# PM_WDT register map
File version: 1
BCM2711 power-management watchdog
Registers are read-write, no defined reset value unless marked. A register's access mark holds for its fields unless they carry their own. Offsets are from the block's base; lines under a group give offsets from that group; [hi:lo] are bit positions; {n}, {i} and the like mark numbered series; 'fields as' and 'values as' point back to an identical list; <NAME> marks a mode.

## Memory map
0x00000000 PM_WDT size 0x28

## PM_WDT
Base 0x00000000
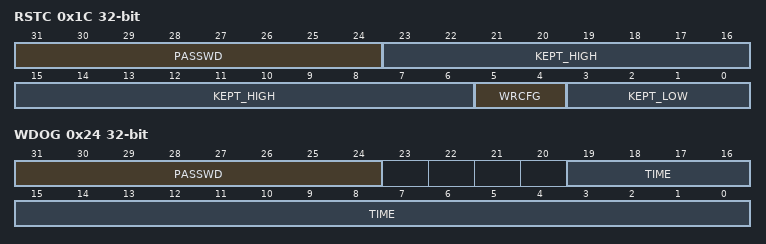
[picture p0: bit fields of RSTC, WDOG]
0x1C RSTC — PM_RSTC: reset control; a write takes effect only with PASSWD's KEY
  [31:24] PASSWD wo — The power-management block's password, with every write
    90=KEY
  [23:6] KEPT_HIGH — Bits no source names; both drivers write them back as read
  [5:4] WRCFG — What the watchdog does when its time runs out
    2=FULL_RESET
  [3:0] KEPT_LOW — Bits no source names; both drivers write them back as read
0x24 WDOG — PM_WDOG: the watchdog's time; a write with PASSWD's KEY starts the count from TIME again
  [31:24] PASSWD wo — The power-management block's password, with every write
    90=KEY
  [19:0] TIME — The time left, in units of 1/65536 s

## Notices in the file
Copyright (c) 2026, Stanislav Sedov <stas@deglitch.com>
SPDX-License-Identifier: BSD-2-Clause
The watchdog of the BCM2711's power-management block (docs/design-platforms.md,
"The watchdog"), written by erXos from the clean-room facts record of the
power-management watchdog, which read only BSD-licensed sources. It holds the facts
that both of these give: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
